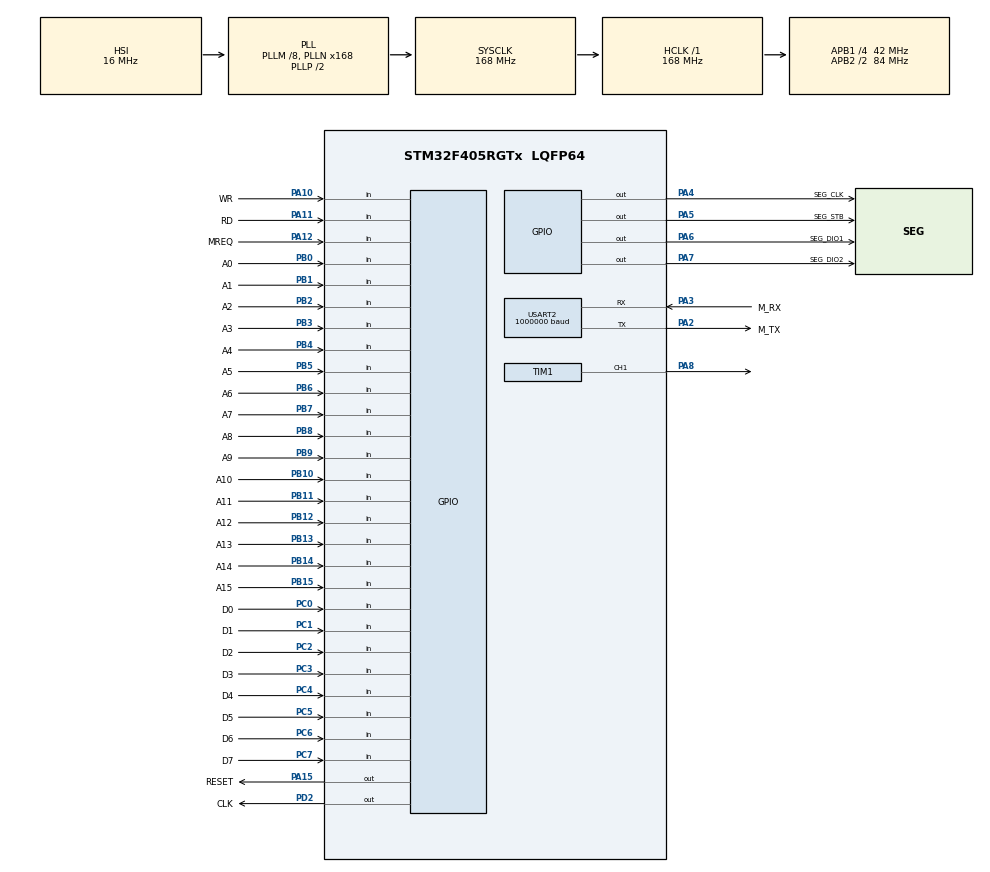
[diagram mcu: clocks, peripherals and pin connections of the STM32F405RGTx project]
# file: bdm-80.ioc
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Mcu.Family=STM32F4
Mcu.Name=STM32F405RGTx
Mcu.Package=LQFP64
NVIC.PriorityGroup=NVIC_PRIORITYGROUP_4
NVIC.TIM1_TRG_COM_TIM11_IRQn=true\:0\:0\:true\:false\:true\:false\:true\:true
NVIC.TIM2_IRQn=true\:3\:0\:true\:false\:true\:true\:true\:true
NVIC.TIM3_IRQn=true\:2\:0\:true\:false\:true\:true\:true\:true
NVIC.TimeBase=TIM1_TRG_COM_TIM11_IRQn
NVIC.TimeBaseIP=TIM11
NVIC.USART2_IRQn=true\:0\:0\:true\:false\:true\:true\:true\:true
PA10.GPIO_Label=WR
PA10.GPIO_PuPd=GPIO_NOPULL
PA10.Signal=GPIO_Input
PA11.GPIO_Label=RD
PA11.GPIO_PuPd=GPIO_NOPULL
PA11.Signal=GPIO_Input
PA12.GPIO_Label=MREQ
PA12.GPIO_PuPd=GPIO_NOPULL
PA12.Signal=GPIO_Input
PA13.Mode=Serial_Wire
PA13.Signal=SYS_JTMS-SWDIO
PA14.Mode=Serial_Wire
PA14.Signal=SYS_JTCK-SWCLK
PA15.GPIO_Label=RESET
PA15.Signal=GPIO_Output
PA2.GPIO_Label=M_TX
PA2.Mode=Asynchronous
PA2.Signal=USART2_TX
PA3.GPIO_Label=M_RX
PA3.Mode=Asynchronous
PA3.Signal=USART2_RX
PA4.GPIO_Label=SEG_CLK
PA4.Signal=GPIO_Output
PA5.GPIO_Label=SEG_STB
PA5.Signal=GPIO_Output
PA6.GPIO_Label=SEG_DIO1
PA6.Signal=GPIO_Output
PA7.GPIO_Label=SEG_DIO2
PA7.Signal=GPIO_Output
PA8.Signal=S_TIM1_CH1
PB0.GPIO_Label=A0
PB0.GPIO_PuPd=GPIO_NOPULL
PB0.Signal=GPIO_Input
PB1.GPIO_Label=A1
PB1.GPIO_PuPd=GPIO_NOPULL
PB1.Signal=GPIO_Input
PB10.GPIO_Label=A10
PB10.GPIO_PuPd=GPIO_NOPULL
PB10.Signal=GPIO_Input
PB11.GPIO_Label=A11
PB11.GPIO_PuPd=GPIO_NOPULL
PB11.Signal=GPIO_Input
PB12.GPIO_Label=A12
PB12.GPIO_PuPd=GPIO_NOPULL
PB12.Signal=GPIO_Input
PB13.GPIO_Label=A13
PB13.GPIO_PuPd=GPIO_NOPULL
PB13.Signal=GPIO_Input
PB14.GPIO_Label=A14
PB14.GPIO_PuPd=GPIO_NOPULL
PB14.Signal=GPIO_Input
PB15.GPIO_Label=A15
PB15.GPIO_PuPd=GPIO_NOPULL
PB15.Signal=GPIO_Input
PB2.GPIO_Label=A2
PB2.GPIO_PuPd=GPIO_NOPULL
PB2.Signal=GPIO_Input
PB3.GPIO_Label=A3
PB3.GPIO_PuPd=GPIO_NOPULL
PB3.Signal=GPIO_Input
PB4.GPIO_Label=A4
PB4.GPIO_PuPd=GPIO_NOPULL
PB4.Signal=GPIO_Input
PB5.GPIO_Label=A5
PB5.GPIO_PuPd=GPIO_NOPULL
PB5.Signal=GPIO_Input
PB6.GPIO_Label=A6
PB6.GPIO_PuPd=GPIO_NOPULL
PB6.Signal=GPIO_Input
PB7.GPIO_Label=A7
PB7.GPIO_PuPd=GPIO_NOPULL
PB7.Signal=GPIO_Input
PB8.GPIO_Label=A8
PB8.GPIO_PuPd=GPIO_NOPULL
PB8.Signal=GPIO_Input
PB9.GPIO_Label=A9
PB9.GPIO_PuPd=GPIO_NOPULL
PB9.Signal=GPIO_Input
PC0.GPIO_Label=D0
PC0.Signal=GPIO_Input
PC1.GPIO_Label=D1
PC1.Signal=GPIO_Input
PC2.GPIO_Label=D2
PC2.Signal=GPIO_Input
PC3.GPIO_Label=D3
PC3.Signal=GPIO_Input
PC4.GPIO_Label=D4
PC4.Signal=GPIO_Input
PC5.GPIO_Label=D5
PC5.Signal=GPIO_Input
PC6.GPIO_Label=D6
PC6.Signal=GPIO_Input
PC7.GPIO_Label=D7
PC7.Signal=GPIO_Input
PD2.GPIO_Label=CLK
PD2.GPIO_Speed=GPIO_SPEED_FREQ_VERY_HIGH
PD2.Signal=GPIO_Output
ProjectManager.HeapSize=0x200
ProjectManager.StackSize=0x400
ProjectManager.TargetToolchain=Makefile
RCC.48MHZClocksFreq_Value=84000000
RCC.AHBFreq_Value=168000000
RCC.APB1CLKDivider=RCC_HCLK_DIV4
RCC.APB1Freq_Value=42000000
RCC.APB1TimFreq_Value=84000000
RCC.APB2CLKDivider=RCC_HCLK_DIV2
RCC.APB2Freq_Value=84000000
RCC.APB2TimFreq_Value=168000000
RCC.CortexFreq_Value=168000000
RCC.HCLKFreq_Value=168000000
RCC.HSE_VALUE=8000000
RCC.HSI_VALUE=16000000
RCC.LSE_VALUE=32768
RCC.PLLM=8
RCC.PLLN=168
RCC.RCC_MCODiv1=RCC_MCODIV_2
RCC.SYSCLKFreq_VALUE=168000000
RCC.SYSCLKSource=RCC_SYSCLKSOURCE_PLLCLK
RCC.VCOOutputFreq_Value=336000000
SH.S_TIM1_CH1.0=TIM1_CH1,PWM Generation1 CH1
TIM1.Channel-PWM\ Generation1\ CH1=TIM_CHANNEL_1
TIM1.Period=1096-1
TIM2.AutoReloadPreload=TIM_AUTORELOAD_PRELOAD_ENABLE
TIM2.Period=50000-1
TIM2.Prescaler=0
TIM3.Period=50000-1
TIM3.Prescaler=84-1
USART2.BaudRate=1000000
USART2.VirtualMode=VM_ASYNC
VP_SYS_VS_tim11.Mode=TIM11
VP_TIM2_VS_ClockSourceINT.Mode=Internal
VP_TIM3_VS_ClockSourceINT.Mode=Internal
board=custom

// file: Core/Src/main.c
/* USER CODE BEGIN Header */
/**
 ******************************************************************************
 * @file           : main.c
 * @brief          : Main program body
 ******************************************************************************
 * @attention
 *
 * Copyright (c) 2022 STMicroelectronics.
 * All rights reserved.
 *
 * This software is licensed under terms that can be found in the LICENSE file
 * in the root directory of this software component.
 * If no LICENSE file comes with this software, it is provided AS-IS.
 *
 ******************************************************************************
 */
/* USER CODE END Header */
#include "main.h"
#include "tim.h"
#include "usart.h"
#include "gpio.h"

/* USER CODE BEGIN Includes */
#include "main_cycle.h"
/* USER CODE END Includes */

void SystemClock_Config(void);

int main(void)
{

  /* MCU Configuration--------------------------------------------------------*/

  /* Reset of all peripherals, Initializes the Flash interface and the Systick. */
  HAL_Init();

  /* Configure the system clock */
  SystemClock_Config();

  /* Initialize all configured peripherals */
  MX_GPIO_Init();
  MX_USART2_UART_Init();
  MX_TIM2_Init();
  MX_TIM1_Init();
  MX_TIM3_Init();
  /* USER CODE BEGIN 2 */
    main_init();
    main_cycle();
  /* USER CODE END 2 */

  /* Infinite loop */
    while (1) {

    }
}

void SystemClock_Config(void)
{
  RCC_OscInitTypeDef RCC_OscInitStruct = {0};
  RCC_ClkInitTypeDef RCC_ClkInitStruct = {0};

  /** Configure the main internal regulator output voltage
  */
  __HAL_RCC_PWR_CLK_ENABLE();
  __HAL_PWR_VOLTAGESCALING_CONFIG(PWR_REGULATOR_VOLTAGE_SCALE1);

  /** Initializes the RCC Oscillators according to the specified parameters
  * in the RCC_OscInitTypeDef structure.
  */
  RCC_OscInitStruct.OscillatorType = RCC_OSCILLATORTYPE_HSI;
  RCC_OscInitStruct.HSIState = RCC_HSI_ON;
  RCC_OscInitStruct.HSICalibrationValue = RCC_HSICALIBRATION_DEFAULT;
  RCC_OscInitStruct.PLL.PLLState = RCC_PLL_ON;
  RCC_OscInitStruct.PLL.PLLSource = RCC_PLLSOURCE_HSI;
  RCC_OscInitStruct.PLL.PLLM = 8;
  RCC_OscInitStruct.PLL.PLLN = 168;
  RCC_OscInitStruct.PLL.PLLP = RCC_PLLP_DIV2;
  RCC_OscInitStruct.PLL.PLLQ = 4;
  if (HAL_RCC_OscConfig(&RCC_OscInitStruct) != HAL_OK)
  {
    Error_Handler();
  }

  /** Initializes the CPU, AHB and APB buses clocks
  */
  RCC_ClkInitStruct.ClockType = RCC_CLOCKTYPE_HCLK|RCC_CLOCKTYPE_SYSCLK
                              |RCC_CLOCKTYPE_PCLK1|RCC_CLOCKTYPE_PCLK2;
  RCC_ClkInitStruct.SYSCLKSource = RCC_SYSCLKSOURCE_PLLCLK;
  RCC_ClkInitStruct.AHBCLKDivider = RCC_SYSCLK_DIV1;
  RCC_ClkInitStruct.APB1CLKDivider = RCC_HCLK_DIV4;
  RCC_ClkInitStruct.APB2CLKDivider = RCC_HCLK_DIV2;

  if (HAL_RCC_ClockConfig(&RCC_ClkInitStruct, FLASH_LATENCY_5) != HAL_OK)
  {
    Error_Handler();
  }
}

void HAL_TIM_PeriodElapsedCallback(TIM_HandleTypeDef *htim)
{
  if (htim->Instance == TIM11) {
    HAL_IncTick();
  }
}

void Error_Handler(void)
{
    __disable_irq();
    while (1) {
    }
}
